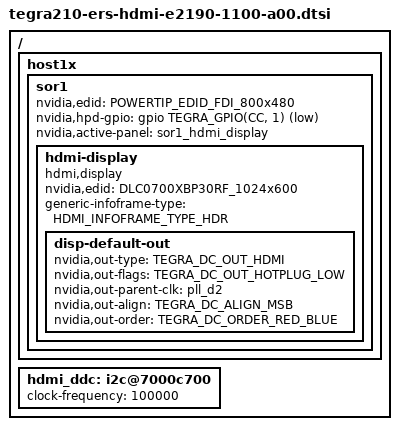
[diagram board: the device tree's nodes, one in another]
/*
 * arch/arm64/boot/dts/tegra210-platforms/tegra210-ers-hdmi-e2190-1100-a00.dtsi
 *
 * Copyright (c) 2014-2017, NVIDIA CORPORATION.  All rights reserved.
 *
 * This program is free software; you can redistribute it and/or modify
 * it under the terms of the GNU General Public License as published by
 * the Free Software Foundation; either version 2 of the License, or
 * (at your option) any later version.
 *
 * This program is distributed in the hope that it will be useful, but WITHOUT
 * ANY WARRANTY; without even the implied warranty of MERCHANTABILITY or
 * FITNESS FOR A PARTICULAR PURPOSE.  See the GNU General Public License for
 * more details.
 *
 * You should have received a copy of the GNU General Public License along
 * with this program; if not, write to the Free Software Foundation, Inc.,
 * 51 Franklin Street, Fifth Floor, Boston, MA  02110-1301, USA.
 */

#include <dt-bindings/display/tegra-dc.h>
#include <dt-bindings/soc/tegra-pmc.h>

#define POWERTIP_EDID_FDI_800x480 \
[00 ff ff ff ff ff ff 00 04 81 04 00 01 00 00 00\
 01 11 01 03 80 0f 08 00 02 42 cc 8f 52 57 99 23\
 12 4c 52 00 00 00 01 01 01 01 01 01 01 01 01 01\
 01 01 01 01 01 01 50 0f 20 c8 30 e0 50 10 9a 0a\
 9a 00 e8 30 32 00 00 1e 00 00 00 10 00 00 00 00\
 00 00 00 00 00 00 00 00 00 00 00 00 00 10 00 00\
 00 00 00 00 00 00 00 00 00 00 00 00 00 00 00 10\
 00 00 00 00 00 00 00 00 00 00 00 00 00 00 00 7e]

#define DLC0700XBP30RF_1024x600 \
[00 ff ff ff ff ff ff 00 05 d7 00 00 00 00 00 00\
 ff 22 01 03 80 32 1f 78 07 ee 95 a3 54 4c 99 26\
 0f 50 54 00 00 00 01 01 01 01 01 01 01 01 01 01\
 01 01 01 01 01 01 c2 10 00 14 41 58 3c 20 74 0a\
 5a 08 14 bc 52 00 00 1e 00 00 00 fd 00 17 f0 0f\
 ff 0f 00 0a 20 20 20 20 20 20 00 00 00 fc 00 48\
 44 54 56 20 31 30 38 30 70 0a 20 20 00 00 00 00\
 00 00 00 00 00 00 00 00 00 00 00 00 00 00 00 b2]
/ {
	host1x {
		sor1 {
			status = "okay";
			nvidia,edid = POWERTIP_EDID_FDI_800x480;
			/* nvidia,ddc-i2c-bus = <&hdmi_ddc>; */
			nvidia,hpd-gpio = <&gpio TEGRA_GPIO(CC, 1) 1>; /* PN7 */
			nvidia,active-panel = <&sor1_hdmi_display>;
			hdmi-display {
				status = "okay";
				compatible = "hdmi,display";
				nvidia,edid = DLC0700XBP30RF_1024x600;
				generic-infoframe-type = <HDMI_INFOFRAME_TYPE_HDR>;
				disp-default-out {
					nvidia,out-type = <TEGRA_DC_OUT_HDMI>;
					nvidia,out-flags = <TEGRA_DC_OUT_HOTPLUG_LOW>;
					nvidia,out-parent-clk = "pll_d2";
					nvidia,out-align = <TEGRA_DC_ALIGN_MSB>;
					nvidia,out-order = <TEGRA_DC_ORDER_RED_BLUE>;
				};
			};
		};
	};
	hdmi_ddc: i2c@7000c700 {
		clock-frequency = <100000>;
	};
};
